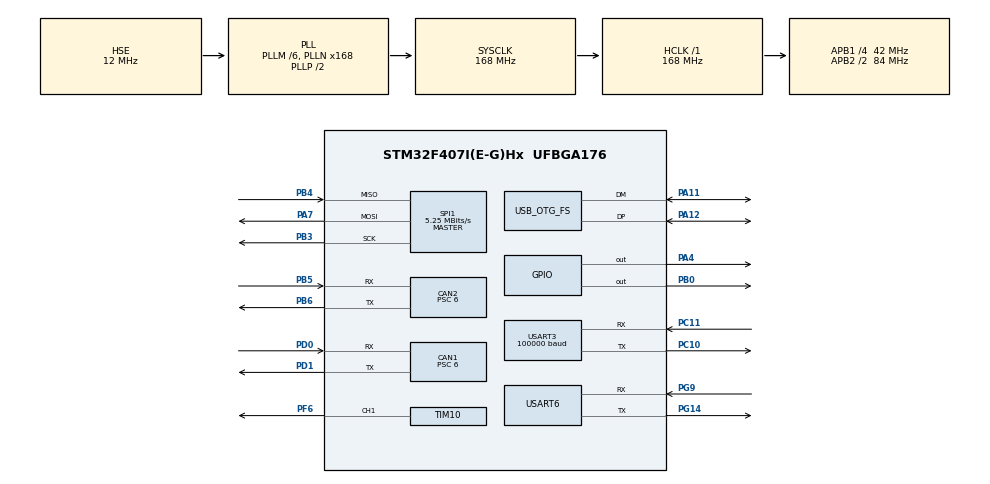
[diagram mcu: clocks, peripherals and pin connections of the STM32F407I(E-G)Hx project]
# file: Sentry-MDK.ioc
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CAN1.BS1=CAN_BS1_3TQ
CAN1.BS2=CAN_BS2_3TQ
CAN1.CalculateBaudRate=1000000
CAN1.CalculateTimeBit=1000
CAN1.CalculateTimeQuantum=142.85714285714286
CAN1.Prescaler=6
CAN2.BS1=CAN_BS1_3TQ
CAN2.BS2=CAN_BS2_3TQ
CAN2.CalculateBaudRate=1000000
CAN2.CalculateTimeBit=1000
CAN2.CalculateTimeQuantum=142.85714285714286
CAN2.Prescaler=6
Dma.Request0=USART3_RX
Dma.USART3_RX.0.Direction=DMA_PERIPH_TO_MEMORY
Dma.USART3_RX.0.FIFOMode=DMA_FIFOMODE_DISABLE
Dma.USART3_RX.0.Instance=DMA1_Stream1
Dma.USART3_RX.0.MemDataAlignment=DMA_MDATAALIGN_BYTE
Dma.USART3_RX.0.MemInc=DMA_MINC_ENABLE
Dma.USART3_RX.0.Mode=DMA_NORMAL
Dma.USART3_RX.0.PeriphDataAlignment=DMA_PDATAALIGN_BYTE
Dma.USART3_RX.0.PeriphInc=DMA_PINC_DISABLE
Dma.USART3_RX.0.Priority=DMA_PRIORITY_LOW
FREERTOS.Tasks01=defaultTask,24,128,StartDefaultTask,Default,NULL,Dynamic,NULL,NULL;Motor,24,512,motorTask,As external,NULL,Dynamic,NULL,NULL;Serial,8,512,serialTask,As external,NULL,Dynamic,NULL,NULL;Gimbal,26,512,gimbalTask,As external,NULL,Dynamic,NULL,NULL;Chassis,26,512,chassisTask,As external,NULL,Dynamic,NULL,NULL;Deamon,26,512,deamonTask,As external,NULL,Dynamic,NULL,NULL;Cmd,32,512,cmdTask,As external,NULL,Dynamic,NULL,NULL;IMU,8,512,imuTask,As external,NULL,Dynamic,NULL,NULL;Shoot,24,128,shootTask,As external,NULL,Dynamic,NULL,NULL
FREERTOS.configTOTAL_HEAP_SIZE=20000
FREERTOS.configUSE_PREEMPTION=1
Mcu.Family=STM32F4
Mcu.Name=STM32F407I(E-G)Hx
Mcu.Package=UFBGA176
NVIC.CAN1_RX0_IRQn=true\:5\:0\:false\:false\:true\:true\:true\:true\:true
NVIC.CAN1_TX_IRQn=true\:5\:0\:false\:false\:true\:true\:true\:true\:true
NVIC.CAN2_RX0_IRQn=true\:5\:0\:false\:false\:true\:true\:true\:true\:true
NVIC.CAN2_TX_IRQn=true\:5\:0\:false\:false\:true\:true\:true\:true\:true
NVIC.DMA1_Stream1_IRQn=true\:5\:0\:false\:false\:true\:true\:false\:true\:true
NVIC.OTG_FS_IRQn=true\:5\:0\:false\:false\:true\:true\:true\:true\:true
NVIC.PriorityGroup=NVIC_PRIORITYGROUP_4
NVIC.SPI1_IRQn=true\:5\:0\:false\:false\:true\:true\:true\:true\:true
NVIC.TIM8_TRG_COM_TIM14_IRQn=true\:15\:0\:false\:false\:true\:false\:false\:true\:true
NVIC.TimeBase=TIM8_TRG_COM_TIM14_IRQn
NVIC.TimeBaseIP=TIM14
NVIC.USART3_IRQn=true\:5\:0\:false\:false\:true\:true\:true\:true\:true
NVIC.USART6_IRQn=true\:5\:0\:false\:false\:true\:true\:true\:true\:true
PA11.Mode=Device_Only
PA11.Signal=USB_OTG_FS_DM
PA12.Mode=Device_Only
PA12.Signal=USB_OTG_FS_DP
PA13.Mode=Serial_Wire
PA13.Signal=SYS_JTMS-SWDIO
PA14.Mode=Serial_Wire
PA14.Signal=SYS_JTCK-SWCLK
PA4.GPIO_PuPd=GPIO_NOPULL
PA4.Signal=GPIO_Output
PA7.Mode=Full_Duplex_Master
PA7.Signal=SPI1_MOSI
PB0.GPIO_PuPd=GPIO_NOPULL
PB0.Signal=GPIO_Output
PB3.Mode=Full_Duplex_Master
PB3.Signal=SPI1_SCK
PB4.Mode=Full_Duplex_Master
PB4.Signal=SPI1_MISO
PB5.Mode=CAN_Activate
PB5.Signal=CAN2_RX
PB6.Mode=CAN_Activate
PB6.Signal=CAN2_TX
PC10.Mode=Asynchronous
PC10.Signal=USART3_TX
PC11.Mode=Asynchronous
PC11.Signal=USART3_RX
PD0.Mode=CAN_Activate
PD0.Signal=CAN1_RX
PD1.Mode=CAN_Activate
PD1.Signal=CAN1_TX
PF6.Signal=S_TIM10_CH1
PG14.Mode=Asynchronous
PG14.Signal=USART6_TX
PG9.Mode=Asynchronous
PG9.Signal=USART6_RX
PH0-OSC_IN.Mode=HSE-External-Oscillator
PH0-OSC_IN.Signal=RCC_OSC_IN
PH1-OSC_OUT.Mode=HSE-External-Oscillator
PH1-OSC_OUT.Signal=RCC_OSC_OUT
ProjectManager.HeapSize=0x8000
ProjectManager.StackSize=0x8000
ProjectManager.TargetToolchain=MDK-ARM V5.32
RCC.48MHZClocksFreq_Value=48000000
RCC.AHBFreq_Value=168000000
RCC.APB1CLKDivider=RCC_HCLK_DIV4
RCC.APB1Freq_Value=42000000
RCC.APB1TimFreq_Value=84000000
RCC.APB2CLKDivider=RCC_HCLK_DIV2
RCC.APB2Freq_Value=84000000
RCC.APB2TimFreq_Value=168000000
RCC.CortexFreq_Value=168000000
RCC.HCLKFreq_Value=168000000
RCC.HSE_VALUE=12000000
RCC.HSI_VALUE=16000000
RCC.LSE_VALUE=32768
RCC.PLLM=6
RCC.PLLN=168
RCC.PLLQ=7
RCC.SYSCLKFreq_VALUE=168000000
RCC.SYSCLKSource=RCC_SYSCLKSOURCE_PLLCLK
RCC.VCOOutputFreq_Value=336000000
SH.S_TIM10_CH1.0=TIM10_CH1,PWM Generation1 CH1
SPI1.BaudRatePrescaler=SPI_BAUDRATEPRESCALER_16
SPI1.CalculateBaudRate=5.25 MBits/s
SPI1.Direction=SPI_DIRECTION_2LINES
SPI1.Mode=SPI_MODE_MASTER
SPI1.VirtualType=VM_MASTER
TIM10.Channel=TIM_CHANNEL_1
TIM10.Prescaler=42000
USART3.BaudRate=100000
USART3.Parity=PARITY_EVEN
USART3.VirtualMode=VM_ASYNC
USART3.WordLength=WORDLENGTH_9B
USART6.VirtualMode=VM_ASYNC
USB_DEVICE.APP_RX_DATA_SIZE-CDC_FS=512
USB_DEVICE.APP_TX_DATA_SIZE-CDC_FS=512
USB_DEVICE.CLASS_NAME_FS=CDC
USB_DEVICE.VirtualMode-CDC_FS=Cdc
USB_DEVICE.VirtualModeFS=Cdc_FS
USB_OTG_FS.VirtualMode=Device_Only
VP_FREERTOS_VS_CMSIS_V2.Mode=CMSIS_V2
VP_SYS_VS_tim14.Mode=TIM14
VP_TIM10_VS_ClockSourceINT.Mode=Enable_Timer
VP_USB_DEVICE_VS_USB_DEVICE_CDC_FS.Mode=CDC_FS
board=custom

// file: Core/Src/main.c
/* USER CODE BEGIN Header */
/**
  ******************************************************************************
  * @file           : main.c
  * @brief          : Main program body
  ******************************************************************************
  * @attention
  *
  * Copyright (c) 2026 STMicroelectronics.
  * All rights reserved.
  *
  * This software is licensed under terms that can be found in the LICENSE file
  * in the root directory of this software component.
  * If no LICENSE file comes with this software, it is provided AS-IS.
  *
  ******************************************************************************
  */
/* USER CODE END Header */
#include "main.h"
#include "cmsis_os.h"
#include "can.h"
#include "dma.h"
#include "spi.h"
#include "tim.h"
#include "usart.h"
#include "usb_device.h"
#include "gpio.h"

/* USER CODE BEGIN Includes */
#include "bsp_can.h"
#include "serial.h"
#include "DJI_motor.h"
#include "pid.h"
#include "math.h"
#include "robotTask.h"

/* USER CODE END Includes */

void SystemClock_Config(void);
void MX_FREERTOS_Init(void);

/* USER CODE BEGIN 0 */

//DJI_motor_instanceTypedef motor08;
//pid_instanceTypedef pid08_speed;
//pid_instanceTypedef pid08_positon;
/* USER CODE END 0 */

int main(void)
{

  /* MCU Configuration--------------------------------------------------------*/

  /* Reset of all peripherals, Initializes the Flash interface and the Systick. */
  HAL_Init();

  /* Configure the system clock */
  SystemClock_Config();

  /* Initialize all configured peripherals */
  MX_GPIO_Init();
  MX_DMA_Init();
  MX_CAN1_Init();
  MX_USART6_UART_Init();
  MX_USART3_UART_Init();
  MX_CAN2_Init();
  MX_SPI1_Init();
  MX_TIM10_Init();
  /* USER CODE BEGIN 2 */

  robot_init();
  /* USER CODE END 2 */

  /* Init scheduler */
  osKernelInitialize();  /* Call init function for freertos objects (in cmsis_os2.c) */
  MX_FREERTOS_Init();

  /* Start scheduler */
  osKernelStart();

  /* We should never get here as control is now taken by the scheduler */

  /* Infinite loop */
  while (1)
  {

  }
}

void SystemClock_Config(void)
{
  RCC_OscInitTypeDef RCC_OscInitStruct = {0};
  RCC_ClkInitTypeDef RCC_ClkInitStruct = {0};

  /** Configure the main internal regulator output voltage
  */
  __HAL_RCC_PWR_CLK_ENABLE();
  __HAL_PWR_VOLTAGESCALING_CONFIG(PWR_REGULATOR_VOLTAGE_SCALE1);

  /** Initializes the RCC Oscillators according to the specified parameters
  * in the RCC_OscInitTypeDef structure.
  */
  RCC_OscInitStruct.OscillatorType = RCC_OSCILLATORTYPE_HSE;
  RCC_OscInitStruct.HSEState = RCC_HSE_ON;
  RCC_OscInitStruct.PLL.PLLState = RCC_PLL_ON;
  RCC_OscInitStruct.PLL.PLLSource = RCC_PLLSOURCE_HSE;
  RCC_OscInitStruct.PLL.PLLM = 6;
  RCC_OscInitStruct.PLL.PLLN = 168;
  RCC_OscInitStruct.PLL.PLLP = RCC_PLLP_DIV2;
  RCC_OscInitStruct.PLL.PLLQ = 7;
  if (HAL_RCC_OscConfig(&RCC_OscInitStruct) != HAL_OK)
  {
    Error_Handler();
  }

  /** Initializes the CPU, AHB and APB buses clocks
  */
  RCC_ClkInitStruct.ClockType = RCC_CLOCKTYPE_HCLK|RCC_CLOCKTYPE_SYSCLK
                              |RCC_CLOCKTYPE_PCLK1|RCC_CLOCKTYPE_PCLK2;
  RCC_ClkInitStruct.SYSCLKSource = RCC_SYSCLKSOURCE_PLLCLK;
  RCC_ClkInitStruct.AHBCLKDivider = RCC_SYSCLK_DIV1;
  RCC_ClkInitStruct.APB1CLKDivider = RCC_HCLK_DIV4;
  RCC_ClkInitStruct.APB2CLKDivider = RCC_HCLK_DIV2;

  if (HAL_RCC_ClockConfig(&RCC_ClkInitStruct, FLASH_LATENCY_5) != HAL_OK)
  {
    Error_Handler();
  }
}

void HAL_TIM_PeriodElapsedCallback(TIM_HandleTypeDef *htim)
{
  if (htim->Instance == TIM14)
  {
    HAL_IncTick();
  }
}

void Error_Handler(void)
{
  __disable_irq();
  while (1)
  {
  }
}

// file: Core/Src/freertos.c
/* USER CODE BEGIN Header */
/**
  ******************************************************************************
  * File Name          : freertos.c
  * Description        : Code for freertos applications
  ******************************************************************************
  * @attention
  *
  * Copyright (c) 2026 STMicroelectronics.
  * All rights reserved.
  *
  * This software is licensed under terms that can be found in the LICENSE file
  * in the root directory of this software component.
  * If no LICENSE file comes with this software, it is provided AS-IS.
  *
  ******************************************************************************
  */
/* USER CODE END Header */

#include "FreeRTOS.h"
#include "task.h"
#include "main.h"
#include "cmsis_os.h"

/* Definitions for defaultTask */
osThreadId_t defaultTaskHandle;
const osThreadAttr_t defaultTask_attributes = {
  .name = "defaultTask",
  .stack_size = 128 * 4,
  .priority = (osPriority_t) osPriorityNormal,
};
/* Definitions for Motor */
osThreadId_t MotorHandle;
const osThreadAttr_t Motor_attributes = {
  .name = "Motor",
  .stack_size = 512 * 4,
  .priority = (osPriority_t) osPriorityNormal,
};
/* Definitions for Serial */
osThreadId_t SerialHandle;
const osThreadAttr_t Serial_attributes = {
  .name = "Serial",
  .stack_size = 512 * 4,
  .priority = (osPriority_t) osPriorityLow,
};
/* Definitions for Gimbal */
osThreadId_t GimbalHandle;
const osThreadAttr_t Gimbal_attributes = {
  .name = "Gimbal",
  .stack_size = 512 * 4,
  .priority = (osPriority_t) osPriorityNormal2,
};
/* Definitions for Chassis */
osThreadId_t ChassisHandle;
const osThreadAttr_t Chassis_attributes = {
  .name = "Chassis",
  .stack_size = 512 * 4,
  .priority = (osPriority_t) osPriorityNormal2,
};
/* Definitions for Deamon */
osThreadId_t DeamonHandle;
const osThreadAttr_t Deamon_attributes = {
  .name = "Deamon",
  .stack_size = 512 * 4,
  .priority = (osPriority_t) osPriorityNormal2,
};
/* Definitions for Cmd */
osThreadId_t CmdHandle;
const osThreadAttr_t Cmd_attributes = {
  .name = "Cmd",
  .stack_size = 512 * 4,
  .priority = (osPriority_t) osPriorityAboveNormal,
};
/* Definitions for IMU */
osThreadId_t IMUHandle;
const osThreadAttr_t IMU_attributes = {
  .name = "IMU",
  .stack_size = 512 * 4,
  .priority = (osPriority_t) osPriorityLow,
};
/* Definitions for Shoot */
osThreadId_t ShootHandle;
const osThreadAttr_t Shoot_attributes = {
  .name = "Shoot",
  .stack_size = 128 * 4,
  .priority = (osPriority_t) osPriorityNormal,
};

void StartDefaultTask(void *argument);
extern void motorTask(void *argument);
extern void serialTask(void *argument);
extern void gimbalTask(void *argument);
extern void chassisTask(void *argument);
extern void deamonTask(void *argument);
extern void cmdTask(void *argument);
extern void imuTask(void *argument);
extern void shootTask(void *argument);

extern void MX_USB_DEVICE_Init(void);
void MX_FREERTOS_Init(void); /* (MISRA C 2004 rule 8.1) */

void MX_FREERTOS_Init(void) {

  /* Create the thread(s) */
  /* creation of defaultTask */
  defaultTaskHandle = osThreadNew(StartDefaultTask, NULL, &defaultTask_attributes);

  /* creation of Motor */
  MotorHandle = osThreadNew(motorTask, NULL, &Motor_attributes);

  /* creation of Serial */
  SerialHandle = osThreadNew(serialTask, NULL, &Serial_attributes);

  /* creation of Gimbal */
  GimbalHandle = osThreadNew(gimbalTask, NULL, &Gimbal_attributes);

  /* creation of Chassis */
  ChassisHandle = osThreadNew(chassisTask, NULL, &Chassis_attributes);

  /* creation of Deamon */
  DeamonHandle = osThreadNew(deamonTask, NULL, &Deamon_attributes);

  /* creation of Cmd */
  CmdHandle = osThreadNew(cmdTask, NULL, &Cmd_attributes);

  /* creation of IMU */
  IMUHandle = osThreadNew(imuTask, NULL, &IMU_attributes);

  /* creation of Shoot */
  ShootHandle = osThreadNew(shootTask, NULL, &Shoot_attributes);

}

void StartDefaultTask(void *argument)
{
  /* init code for USB_DEVICE */
  MX_USB_DEVICE_Init();
  for(;;)
  {
    osDelay(1);
  }
}
